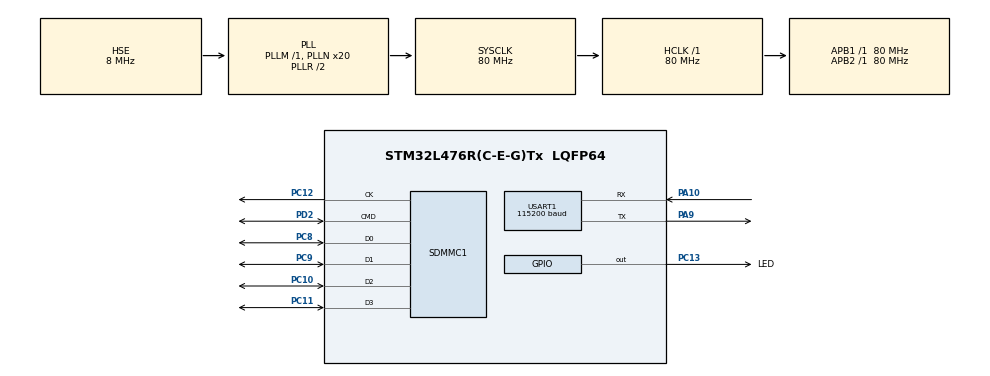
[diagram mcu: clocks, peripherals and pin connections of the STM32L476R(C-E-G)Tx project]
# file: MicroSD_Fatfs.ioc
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FATFS.SD_BSP_CODE=0
FATFS.USE_DMA_CODE_SD=0
FATFS._CODE_PAGE=850
FATFS._FS_EXFAT=1
FATFS._FS_LOCK=2
FATFS._FS_MINIMIZE=0
FATFS._FS_NOFSINFO=0
FATFS._FS_NORTC=0
FATFS._FS_READONLY=0
FATFS._FS_REENTRANT=0
FATFS._FS_RPATH=0
FATFS._FS_TIMEOUT=1000
FATFS._FS_TINY=0
FATFS._HSD=hsd1
FATFS._LFN_UNICODE=0
FATFS._MAX_LFN=255
FATFS._MAX_SS=512
FATFS._MIN_SS=512
FATFS._MULTI_PARTITION=0
FATFS._STRF_ENCODE=3
FATFS._USE_CHMOD=0
FATFS._USE_EXPAND=0
FATFS._USE_FASTSEEK=1
FATFS._USE_FIND=0
FATFS._USE_FORWARD=0
FATFS._USE_LABEL=0
FATFS._USE_LFN=2
FATFS._USE_MKFS=1
FATFS._USE_STRFUNC=2
FATFS._USE_TRIM=0
FATFS._VOLUMES=1
Mcu.Family=STM32L4
Mcu.Name=STM32L476R(C-E-G)Tx
Mcu.Package=LQFP64
NVIC.PriorityGroup=NVIC_PRIORITYGROUP_4
NVIC.SDMMC1_IRQn=true\:0\:0\:false\:false\:true\:true\:true\:true
PA10.Mode=Asynchronous
PA10.Signal=USART1_RX
PA13\ (JTMS-SWDIO).Mode=Serial_Wire
PA13\ (JTMS-SWDIO).Signal=SYS_JTMS-SWDIO
PA14\ (JTCK-SWCLK).Mode=Serial_Wire
PA14\ (JTCK-SWCLK).Signal=SYS_JTCK-SWCLK
PA9.Mode=Asynchronous
PA9.Signal=USART1_TX
PC10.GPIO_PuPd=GPIO_PULLUP
PC10.GPIO_Speed_High_Default=GPIO_SPEED_FREQ_MEDIUM
PC10.Mode=SD_4_bits_Wide_bus
PC10.Signal=SDMMC1_D2
PC11.GPIO_PuPd=GPIO_PULLUP
PC11.GPIO_Speed_High_Default=GPIO_SPEED_FREQ_MEDIUM
PC11.Mode=SD_4_bits_Wide_bus
PC11.Signal=SDMMC1_D3
PC12.GPIO_PuPd=GPIO_PULLUP
PC12.GPIO_Speed_High_Default=GPIO_SPEED_FREQ_MEDIUM
PC12.Mode=SD_4_bits_Wide_bus
PC12.Signal=SDMMC1_CK
PC13.GPIO_Label=LED
PC13.PinState=GPIO_PIN_SET
PC13.Signal=GPIO_Output
PC8.GPIO_PuPd=GPIO_PULLUP
PC8.GPIO_Speed_High_Default=GPIO_SPEED_FREQ_MEDIUM
PC8.Mode=SD_4_bits_Wide_bus
PC8.Signal=SDMMC1_D0
PC9.GPIO_PuPd=GPIO_PULLUP
PC9.GPIO_Speed_High_Default=GPIO_SPEED_FREQ_MEDIUM
PC9.Mode=SD_4_bits_Wide_bus
PC9.Signal=SDMMC1_D1
PD2.GPIO_PuPd=GPIO_PULLUP
PD2.GPIO_Speed_High_Default=GPIO_SPEED_FREQ_MEDIUM
PD2.Mode=SD_4_bits_Wide_bus
PD2.Signal=SDMMC1_CMD
PH0-OSC_IN\ (PH0).Mode=HSE-External-Oscillator
PH0-OSC_IN\ (PH0).Signal=RCC_OSC_IN
PH1-OSC_OUT\ (PH1).Mode=HSE-External-Oscillator
PH1-OSC_OUT\ (PH1).Signal=RCC_OSC_OUT
ProjectManager.HeapSize=0x400
ProjectManager.StackSize=0x1000
ProjectManager.TargetToolchain=MDK-ARM V5.32
RCC.ADCFreq_Value=32000000
RCC.AHBFreq_Value=80000000
RCC.APB1Freq_Value=80000000
RCC.APB1TimFreq_Value=80000000
RCC.APB2Freq_Value=80000000
RCC.APB2TimFreq_Value=80000000
RCC.CortexFreq_Value=80000000
RCC.FLatency=FLASH_LATENCY_4
RCC.HCLKFreq_Value=80000000
RCC.HSE_VALUE=8000000
RCC.HSI_VALUE=16000000
RCC.LSE_VALUE=32768
RCC.MSI_VALUE=4000000
RCC.PLLN=20
RCC.PLLSourceVirtual=RCC_PLLSOURCE_HSE
RCC.SYSCLKFreq_VALUE=80000000
RCC.SYSCLKSource=RCC_SYSCLKSOURCE_PLLCLK
RCC.USBFreq_Value=32000000
RCC.VCOOutputFreq_Value=160000000
SDMMC1.ClockBypass=SDMMC_CLOCK_BYPASS_DISABLE
SDMMC1.ClockDiv=2
SDMMC1.ClockEdge=SDMMC_CLOCK_EDGE_RISING
SDMMC1.ClockPowerSave=SDMMC_CLOCK_POWER_SAVE_DISABLE
SDMMC1.HardwareFlowControl=SDMMC_HARDWARE_FLOW_CONTROL_ENABLE
USART1.AutoBaudRateEnableParam=UART_ADVFEATURE_AUTOBAUDRATE_DISABLE
USART1.BaudRate=115200
USART1.DMADisableonRxErrorParam=ADVFEATURE_DMA_ENABLEONRXERROR
USART1.DataInvertParam=ADVFEATURE_DATAINV_DISABLE
USART1.MSBFirstParam=ADVFEATURE_MSBFIRST_DISABLE
USART1.Mode=MODE_TX_RX
USART1.OneBitSampling=UART_ONE_BIT_SAMPLE_DISABLE
USART1.OverSampling=UART_OVERSAMPLING_16
USART1.OverrunDisableParam=ADVFEATURE_OVERRUN_ENABLE
USART1.Parity=PARITY_NONE
USART1.RxPinLevelInvertParam=ADVFEATURE_RXINV_DISABLE
USART1.StopBits=STOPBITS_1
USART1.SwapParam=ADVFEATURE_SWAP_DISABLE
USART1.TxPinLevelInvertParam=ADVFEATURE_TXINV_DISABLE
USART1.VirtualMode-Asynchronous=VM_ASYNC
USART1.WordLength=WORDLENGTH_8B
VP_FATFS_VS_SDIO.Mode=SDIO
board=custom

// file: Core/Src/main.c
/* USER CODE BEGIN Header */
/**
  ******************************************************************************
  * @file           : main.c
  * @brief          : Main program body
  ******************************************************************************
  * @attention
  *
  * <h2><center>&copy; Copyright (c) 2022 STMicroelectronics.
  * All rights reserved.</center></h2>
  *
  * This software component is licensed by ST under Ultimate Liberty license
  * SLA0044, the "License"; You may not use this file except in compliance with
  * the License. You may obtain a copy of the License at:
  *                             www.st.com/SLA0044
  *
  ******************************************************************************
  */
/* USER CODE END Header */
#include "main.h"
#include "fatfs.h"
#include "sdmmc.h"
#include "usart.h"
#include "gpio.h"

void SystemClock_Config(void);
/* USER CODE BEGIN PFP */
void app_fatfs(void);

/* USER CODE END PFP */

int main(void)
{

  /* MCU Configuration--------------------------------------------------------*/

  /* Reset of all peripherals, Initializes the Flash interface and the Systick. */
  HAL_Init();

  /* Configure the system clock */
  SystemClock_Config();

  /* Initialize all configured peripherals */
  MX_GPIO_Init();
  MX_USART1_UART_Init();
  MX_FATFS_Init();
  MX_SDMMC1_SD_Init();
  /* USER CODE BEGIN 2 */
	app_fatfs();
  /* USER CODE END 2 */

  /* Infinite loop */
  while (1)
  {

  }
}

void SystemClock_Config(void)
{
  RCC_OscInitTypeDef RCC_OscInitStruct = {0};
  RCC_ClkInitTypeDef RCC_ClkInitStruct = {0};

  /** Configure the main internal regulator output voltage
  */
  if (HAL_PWREx_ControlVoltageScaling(PWR_REGULATOR_VOLTAGE_SCALE1) != HAL_OK)
  {
    Error_Handler();
  }

  /** Initializes the RCC Oscillators according to the specified parameters
  * in the RCC_OscInitTypeDef structure.
  */
  RCC_OscInitStruct.OscillatorType = RCC_OSCILLATORTYPE_HSE;
  RCC_OscInitStruct.HSEState = RCC_HSE_ON;
  RCC_OscInitStruct.PLL.PLLState = RCC_PLL_ON;
  RCC_OscInitStruct.PLL.PLLSource = RCC_PLLSOURCE_HSE;
  RCC_OscInitStruct.PLL.PLLM = 1;
  RCC_OscInitStruct.PLL.PLLN = 20;
  RCC_OscInitStruct.PLL.PLLP = RCC_PLLP_DIV7;
  RCC_OscInitStruct.PLL.PLLQ = RCC_PLLQ_DIV2;
  RCC_OscInitStruct.PLL.PLLR = RCC_PLLR_DIV2;
  if (HAL_RCC_OscConfig(&RCC_OscInitStruct) != HAL_OK)
  {
    Error_Handler();
  }

  /** Initializes the CPU, AHB and APB buses clocks
  */
  RCC_ClkInitStruct.ClockType = RCC_CLOCKTYPE_HCLK|RCC_CLOCKTYPE_SYSCLK
                              |RCC_CLOCKTYPE_PCLK1|RCC_CLOCKTYPE_PCLK2;
  RCC_ClkInitStruct.SYSCLKSource = RCC_SYSCLKSOURCE_PLLCLK;
  RCC_ClkInitStruct.AHBCLKDivider = RCC_SYSCLK_DIV1;
  RCC_ClkInitStruct.APB1CLKDivider = RCC_HCLK_DIV1;
  RCC_ClkInitStruct.APB2CLKDivider = RCC_HCLK_DIV1;

  if (HAL_RCC_ClockConfig(&RCC_ClkInitStruct, FLASH_LATENCY_4) != HAL_OK)
  {
    Error_Handler();
  }
}

void Error_Handler(void)
{
  /* USER CODE BEGIN Error_Handler_Debug */
  /* User can add his own implementation to report the HAL error return state */
  //__disable_irq();
  while (1)
  {
			HAL_GPIO_TogglePin(LED_GPIO_Port, LED_Pin);
			HAL_Delay(300);
  }
  /* USER CODE END Error_Handler_Debug */
}
